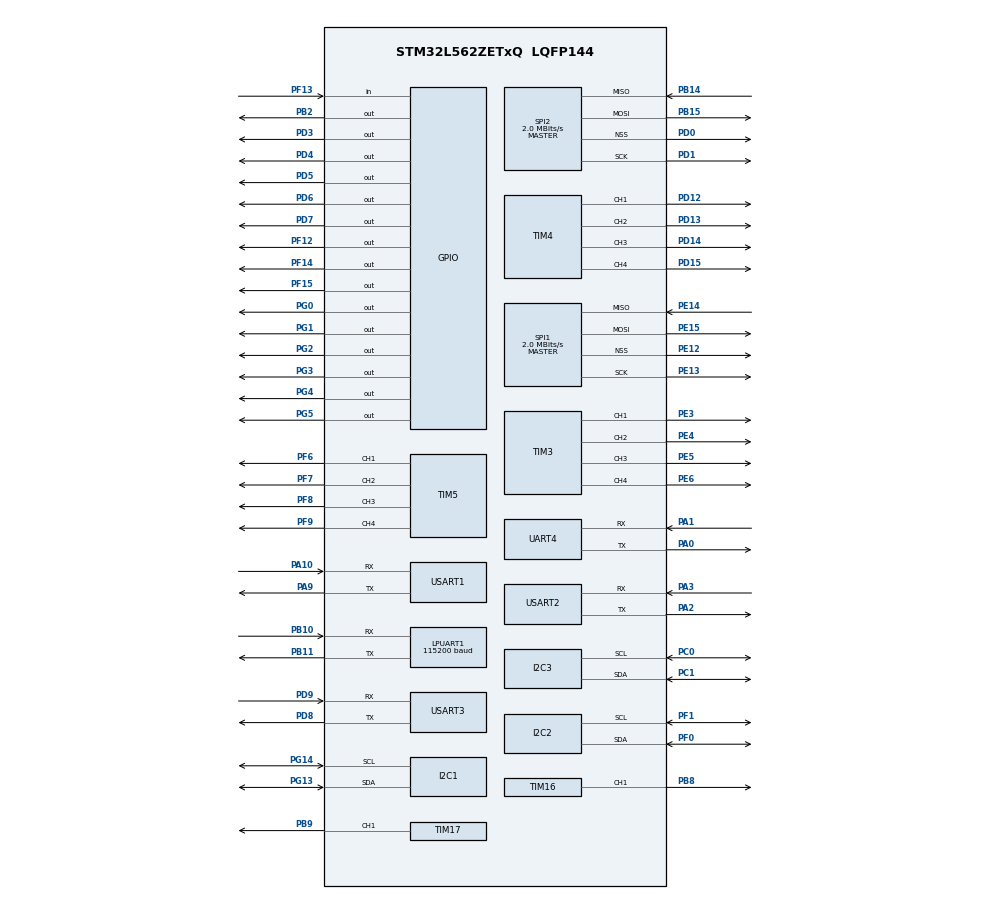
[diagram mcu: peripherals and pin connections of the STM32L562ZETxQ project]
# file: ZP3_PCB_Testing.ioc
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LPUART1.BaudRate=115200
Mcu.Family=STM32L5
Mcu.Name=STM32L562ZETxQ
Mcu.Package=LQFP144
NVIC.PriorityGroup=NVIC_PRIORITYGROUP_3
PA0.Mode=Asynchronous
PA0.Signal=UART4_TX
PA1.Mode=Asynchronous
PA1.Signal=UART4_RX
PA10.Mode=Asynchronous
PA10.Signal=USART1_RX
PA2.Mode=Asynchronous
PA2.Signal=USART2_TX
PA3.Mode=Asynchronous
PA3.Signal=USART2_RX
PA9.Mode=Asynchronous
PA9.Signal=USART1_TX
PB10.Mode=Asynchronous
PB10.Signal=LPUART1_RX
PB11.Mode=Asynchronous
PB11.Signal=LPUART1_TX
PB14.Mode=Full_Duplex_Master
PB14.Signal=SPI2_MISO
PB15.Mode=Full_Duplex_Master
PB15.Signal=SPI2_MOSI
PB2.Signal=GPIO_Output
PB8.Signal=S_TIM16_CH1
PB9.Signal=S_TIM17_CH1
PC0.Mode=I2C
PC0.Signal=I2C3_SCL
PC1.Mode=I2C
PC1.Signal=I2C3_SDA
PD0.Mode=NSS_Signal_Hard_Output
PD0.Signal=SPI2_NSS
PD1.Mode=Full_Duplex_Master
PD1.Signal=SPI2_SCK
PD12.Signal=S_TIM4_CH1
PD13.Signal=S_TIM4_CH2
PD14.Signal=S_TIM4_CH3
PD15.Signal=S_TIM4_CH4
PD3.Signal=GPIO_Output
PD4.Signal=GPIO_Output
PD5.Signal=GPIO_Output
PD6.Signal=GPIO_Output
PD7.Signal=GPIO_Output
PD8.Mode=Asynchronous
PD8.Signal=USART3_TX
PD9.Mode=Asynchronous
PD9.Signal=USART3_RX
PE12.Mode=NSS_Signal_Hard_Output
PE12.Signal=SPI1_NSS
PE13.Mode=Full_Duplex_Master
PE13.Signal=SPI1_SCK
PE14.Mode=Full_Duplex_Master
PE14.Signal=SPI1_MISO
PE15.Mode=Full_Duplex_Master
PE15.Signal=SPI1_MOSI
PE3.Signal=S_TIM3_CH1
PE4.Signal=S_TIM3_CH2
PE5.Signal=S_TIM3_CH3
PE6.Signal=S_TIM3_CH4
PF0.Mode=I2C
PF0.Signal=I2C2_SDA
PF1.Mode=I2C
PF1.Signal=I2C2_SCL
PF12.Signal=GPIO_Output
PF13.Signal=GPIO_Input
PF14.Signal=GPIO_Output
PF15.Signal=GPIO_Output
PF6.Signal=S_TIM5_CH1
PF7.Signal=S_TIM5_CH2
PF8.Signal=S_TIM5_CH3
PF9.Signal=S_TIM5_CH4
PG0.Signal=GPIO_Output
PG1.Signal=GPIO_Output
PG13.Mode=I2C
PG13.Signal=I2C1_SDA
PG14.Mode=I2C
PG14.Signal=I2C1_SCL
PG2.Signal=GPIO_Output
PG3.Signal=GPIO_Output
PG4.Signal=GPIO_Output
PG5.Signal=GPIO_Output
ProjectManager.HeapSize=0x200
ProjectManager.StackSize=0x400
ProjectManager.TargetToolchain=STM32CubeIDE
RCC.HSE_VALUE=16000000
RCC.HSI48_VALUE=48000000
RCC.HSI_VALUE=16000000
RCC.LSE_VALUE=32768
RCC.MSI_VALUE=4000000
RCC.VCOOutputFreq_Value=32000000
SH.S_TIM16_CH1.0=TIM16_CH1,PWM Generation1 CH1
SH.S_TIM17_CH1.0=TIM17_CH1,PWM Generation1 CH1
SH.S_TIM3_CH1.0=TIM3_CH1,PWM Generation1 CH1
SH.S_TIM3_CH2.0=TIM3_CH2,PWM Generation2 CH2
SH.S_TIM3_CH3.0=TIM3_CH3,PWM Generation3 CH3
SH.S_TIM3_CH4.0=TIM3_CH4,PWM Generation4 CH4
SH.S_TIM4_CH1.0=TIM4_CH1,PWM Generation1 CH1
SH.S_TIM4_CH2.0=TIM4_CH2,PWM Generation2 CH2
SH.S_TIM4_CH3.0=TIM4_CH3,PWM Generation3 CH3
SH.S_TIM4_CH4.0=TIM4_CH4,PWM Generation4 CH4
SH.S_TIM5_CH1.0=TIM5_CH1,PWM Generation1 CH1
SH.S_TIM5_CH2.0=TIM5_CH2,PWM Generation2 CH2
SH.S_TIM5_CH3.0=TIM5_CH3,PWM Generation3 CH3
SH.S_TIM5_CH4.0=TIM5_CH4,PWM Generation4 CH4
SPI1.CalculateBaudRate=2.0 MBits/s
SPI1.Direction=SPI_DIRECTION_2LINES
SPI1.Mode=SPI_MODE_MASTER
SPI1.VirtualNSS=VM_NSSHARD
SPI1.VirtualType=VM_MASTER
SPI2.CalculateBaudRate=2.0 MBits/s
SPI2.DataSize=SPI_DATASIZE_8BIT
SPI2.Direction=SPI_DIRECTION_2LINES
SPI2.Mode=SPI_MODE_MASTER
SPI2.VirtualNSS=VM_NSSHARD
SPI2.VirtualType=VM_MASTER
TIM16.Channel=TIM_CHANNEL_1
TIM17.Channel=TIM_CHANNEL_1
TIM3.Channel-PWM\ Generation1\ CH1=TIM_CHANNEL_1
TIM3.Channel-PWM\ Generation2\ CH2=TIM_CHANNEL_2
TIM3.Channel-PWM\ Generation3\ CH3=TIM_CHANNEL_3
TIM3.Channel-PWM\ Generation4\ CH4=TIM_CHANNEL_4
TIM4.Channel-PWM\ Generation1\ CH1=TIM_CHANNEL_1
TIM4.Channel-PWM\ Generation2\ CH2=TIM_CHANNEL_2
TIM4.Channel-PWM\ Generation3\ CH3=TIM_CHANNEL_3
TIM4.Channel-PWM\ Generation4\ CH4=TIM_CHANNEL_4
TIM5.Channel-PWM\ Generation1\ CH1=TIM_CHANNEL_1
TIM5.Channel-PWM\ Generation2\ CH2=TIM_CHANNEL_2
TIM5.Channel-PWM\ Generation3\ CH3=TIM_CHANNEL_3
TIM5.Channel-PWM\ Generation4\ CH4=TIM_CHANNEL_4
USART1.VirtualMode-Asynchronous=VM_ASYNC
USART2.VirtualMode-Asynchronous=VM_ASYNC
USART3.VirtualMode-Asynchronous=VM_ASYNC
VP_TIM16_VS_ClockSourceINT.Mode=Enable_Timer
VP_TIM17_VS_ClockSourceINT.Mode=Enable_Timer
board=custom

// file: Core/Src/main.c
/* USER CODE BEGIN Header */
/**
  ******************************************************************************
  * @file           : main.c
  * @brief          : Main program body
  ******************************************************************************
  * @attention
  *
  * Copyright (c) 2023 STMicroelectronics.
  * All rights reserved.
  *
  * This software is licensed under terms that can be found in the LICENSE file
  * in the root directory of this software component.
  * If no LICENSE file comes with this software, it is provided AS-IS.
  *
  ******************************************************************************
  */
/* USER CODE END Header */
#include "main.h"

I2C_HandleTypeDef hi2c1;
I2C_HandleTypeDef hi2c2;
I2C_HandleTypeDef hi2c3;

UART_HandleTypeDef hlpuart1;
UART_HandleTypeDef huart4;
UART_HandleTypeDef huart1;
UART_HandleTypeDef huart2;
UART_HandleTypeDef huart3;

SPI_HandleTypeDef hspi1;
SPI_HandleTypeDef hspi2;

TIM_HandleTypeDef htim3;
TIM_HandleTypeDef htim4;
TIM_HandleTypeDef htim5;
TIM_HandleTypeDef htim16;
TIM_HandleTypeDef htim17;

void SystemClock_Config(void);
static void MX_GPIO_Init(void);
static void MX_I2C1_Init(void);
static void MX_I2C2_Init(void);
static void MX_I2C3_Init(void);
static void MX_LPUART1_UART_Init(void);
static void MX_UART4_Init(void);
static void MX_USART1_UART_Init(void);
static void MX_USART2_UART_Init(void);
static void MX_USART3_UART_Init(void);
static void MX_SPI1_Init(void);
static void MX_SPI2_Init(void);
static void MX_TIM3_Init(void);
static void MX_TIM4_Init(void);
static void MX_TIM5_Init(void);
static void MX_TIM16_Init(void);
static void MX_TIM17_Init(void);

/* USER CODE BEGIN 0 */
void toggle_all_GPIO(void)
{

	HAL_GPIO_TogglePin(GPIOB, GPIO_PIN_2);

	  /*Configure GPIO pin Output Level */
	HAL_GPIO_TogglePin(GPIOF, GPIO_PIN_12|GPIO_PIN_14|GPIO_PIN_15);

	  /*Configure GPIO pin Output Level */
	HAL_GPIO_TogglePin(GPIOG, GPIO_PIN_0|GPIO_PIN_1|GPIO_PIN_2|GPIO_PIN_3
	                          |GPIO_PIN_4|GPIO_PIN_5);

	  /*Configure GPIO pin Output Level */
	HAL_GPIO_TogglePin(GPIOD, GPIO_PIN_3|GPIO_PIN_4|GPIO_PIN_5|GPIO_PIN_6
	                          |GPIO_PIN_7);
}

/* USER CODE END 0 */

int main(void)
{

  /* MCU Configuration--------------------------------------------------------*/

  /* Reset of all peripherals, Initializes the Flash interface and the Systick. */
  HAL_Init();

  /* Configure the system clock */
  SystemClock_Config();

  /* Initialize all configured peripherals */
  MX_GPIO_Init();
  MX_I2C1_Init();
  MX_I2C2_Init();
  MX_I2C3_Init();
  MX_LPUART1_UART_Init();
  MX_UART4_Init();
  MX_USART1_UART_Init();
  MX_USART2_UART_Init();
  MX_USART3_UART_Init();
  MX_SPI1_Init();
  MX_SPI2_Init();
  MX_TIM3_Init();
  MX_TIM4_Init();
  MX_TIM5_Init();
  MX_TIM16_Init();
  MX_TIM17_Init();

  /* Infinite loop */
  while (1)
  {
	  toggle_all_GPIO();
	  HAL_Delay(500);
  }
}

void SystemClock_Config(void)
{
  RCC_OscInitTypeDef RCC_OscInitStruct = {0};
  RCC_ClkInitTypeDef RCC_ClkInitStruct = {0};

  /** Configure the main internal regulator output voltage
  */
  if (HAL_PWREx_ControlVoltageScaling(PWR_REGULATOR_VOLTAGE_SCALE2) != HAL_OK)
  {
    Error_Handler();
  }

  /** Initializes the RCC Oscillators according to the specified parameters
  * in the RCC_OscInitTypeDef structure.
  */
  RCC_OscInitStruct.OscillatorType = RCC_OSCILLATORTYPE_MSI;
  RCC_OscInitStruct.MSIState = RCC_MSI_ON;
  RCC_OscInitStruct.MSICalibrationValue = RCC_MSICALIBRATION_DEFAULT;
  RCC_OscInitStruct.MSIClockRange = RCC_MSIRANGE_6;
  RCC_OscInitStruct.PLL.PLLState = RCC_PLL_NONE;
  if (HAL_RCC_OscConfig(&RCC_OscInitStruct) != HAL_OK)
  {
    Error_Handler();
  }

  /** Initializes the CPU, AHB and APB buses clocks
  */
  RCC_ClkInitStruct.ClockType = RCC_CLOCKTYPE_HCLK|RCC_CLOCKTYPE_SYSCLK
                              |RCC_CLOCKTYPE_PCLK1|RCC_CLOCKTYPE_PCLK2;
  RCC_ClkInitStruct.SYSCLKSource = RCC_SYSCLKSOURCE_MSI;
  RCC_ClkInitStruct.AHBCLKDivider = RCC_SYSCLK_DIV1;
  RCC_ClkInitStruct.APB1CLKDivider = RCC_HCLK_DIV1;
  RCC_ClkInitStruct.APB2CLKDivider = RCC_HCLK_DIV1;

  if (HAL_RCC_ClockConfig(&RCC_ClkInitStruct, FLASH_LATENCY_0) != HAL_OK)
  {
    Error_Handler();
  }
}

static void MX_I2C1_Init(void)
{

  hi2c1.Instance = I2C1;
  hi2c1.Init.Timing = 0x00000E14;
  hi2c1.Init.OwnAddress1 = 0;
  hi2c1.Init.AddressingMode = I2C_ADDRESSINGMODE_7BIT;
  hi2c1.Init.DualAddressMode = I2C_DUALADDRESS_DISABLE;
  hi2c1.Init.OwnAddress2 = 0;
  hi2c1.Init.OwnAddress2Masks = I2C_OA2_NOMASK;
  hi2c1.Init.GeneralCallMode = I2C_GENERALCALL_DISABLE;
  hi2c1.Init.NoStretchMode = I2C_NOSTRETCH_DISABLE;
  if (HAL_I2C_Init(&hi2c1) != HAL_OK)
  {
    Error_Handler();
  }

  /** Configure Analogue filter
  */
  if (HAL_I2CEx_ConfigAnalogFilter(&hi2c1, I2C_ANALOGFILTER_ENABLE) != HAL_OK)
  {
    Error_Handler();
  }

  /** Configure Digital filter
  */
  if (HAL_I2CEx_ConfigDigitalFilter(&hi2c1, 0) != HAL_OK)
  {
    Error_Handler();
  }

}

static void MX_I2C2_Init(void)
{

  hi2c2.Instance = I2C2;
  hi2c2.Init.Timing = 0x00000E14;
  hi2c2.Init.OwnAddress1 = 0;
  hi2c2.Init.AddressingMode = I2C_ADDRESSINGMODE_7BIT;
  hi2c2.Init.DualAddressMode = I2C_DUALADDRESS_DISABLE;
  hi2c2.Init.OwnAddress2 = 0;
  hi2c2.Init.OwnAddress2Masks = I2C_OA2_NOMASK;
  hi2c2.Init.GeneralCallMode = I2C_GENERALCALL_DISABLE;
  hi2c2.Init.NoStretchMode = I2C_NOSTRETCH_DISABLE;
  if (HAL_I2C_Init(&hi2c2) != HAL_OK)
  {
    Error_Handler();
  }

  /** Configure Analogue filter
  */
  if (HAL_I2CEx_ConfigAnalogFilter(&hi2c2, I2C_ANALOGFILTER_ENABLE) != HAL_OK)
  {
    Error_Handler();
  }

  /** Configure Digital filter
  */
  if (HAL_I2CEx_ConfigDigitalFilter(&hi2c2, 0) != HAL_OK)
  {
    Error_Handler();
  }

}

static void MX_I2C3_Init(void)
{

  hi2c3.Instance = I2C3;
  hi2c3.Init.Timing = 0x00000E14;
  hi2c3.Init.OwnAddress1 = 0;
  hi2c3.Init.AddressingMode = I2C_ADDRESSINGMODE_7BIT;
  hi2c3.Init.DualAddressMode = I2C_DUALADDRESS_DISABLE;
  hi2c3.Init.OwnAddress2 = 0;
  hi2c3.Init.OwnAddress2Masks = I2C_OA2_NOMASK;
  hi2c3.Init.GeneralCallMode = I2C_GENERALCALL_DISABLE;
  hi2c3.Init.NoStretchMode = I2C_NOSTRETCH_DISABLE;
  if (HAL_I2C_Init(&hi2c3) != HAL_OK)
  {
    Error_Handler();
  }

  /** Configure Analogue filter
  */
  if (HAL_I2CEx_ConfigAnalogFilter(&hi2c3, I2C_ANALOGFILTER_ENABLE) != HAL_OK)
  {
    Error_Handler();
  }

  /** Configure Digital filter
  */
  if (HAL_I2CEx_ConfigDigitalFilter(&hi2c3, 0) != HAL_OK)
  {
    Error_Handler();
  }

}

static void MX_LPUART1_UART_Init(void)
{

  hlpuart1.Instance = LPUART1;
  hlpuart1.Init.BaudRate = 115200;
  hlpuart1.Init.WordLength = UART_WORDLENGTH_8B;
  hlpuart1.Init.StopBits = UART_STOPBITS_1;
  hlpuart1.Init.Parity = UART_PARITY_NONE;
  hlpuart1.Init.Mode = UART_MODE_TX_RX;
  hlpuart1.Init.HwFlowCtl = UART_HWCONTROL_NONE;
  hlpuart1.Init.OneBitSampling = UART_ONE_BIT_SAMPLE_DISABLE;
  hlpuart1.Init.ClockPrescaler = UART_PRESCALER_DIV1;
  hlpuart1.AdvancedInit.AdvFeatureInit = UART_ADVFEATURE_NO_INIT;
  hlpuart1.FifoMode = UART_FIFOMODE_DISABLE;
  if (HAL_UART_Init(&hlpuart1) != HAL_OK)
  {
    Error_Handler();
  }
  if (HAL_UARTEx_SetTxFifoThreshold(&hlpuart1, UART_TXFIFO_THRESHOLD_1_8) != HAL_OK)
  {
    Error_Handler();
  }
  if (HAL_UARTEx_SetRxFifoThreshold(&hlpuart1, UART_RXFIFO_THRESHOLD_1_8) != HAL_OK)
  {
    Error_Handler();
  }
  if (HAL_UARTEx_DisableFifoMode(&hlpuart1) != HAL_OK)
  {
    Error_Handler();
  }

}

static void MX_UART4_Init(void)
{

  huart4.Instance = UART4;
  huart4.Init.BaudRate = 115200;
  huart4.Init.WordLength = UART_WORDLENGTH_8B;
  huart4.Init.StopBits = UART_STOPBITS_1;
  huart4.Init.Parity = UART_PARITY_NONE;
  huart4.Init.Mode = UART_MODE_TX_RX;
  huart4.Init.HwFlowCtl = UART_HWCONTROL_NONE;
  huart4.Init.OverSampling = UART_OVERSAMPLING_16;
  huart4.Init.OneBitSampling = UART_ONE_BIT_SAMPLE_DISABLE;
  huart4.Init.ClockPrescaler = UART_PRESCALER_DIV1;
  huart4.AdvancedInit.AdvFeatureInit = UART_ADVFEATURE_NO_INIT;
  if (HAL_UART_Init(&huart4) != HAL_OK)
  {
    Error_Handler();
  }
  if (HAL_UARTEx_SetTxFifoThreshold(&huart4, UART_TXFIFO_THRESHOLD_1_8) != HAL_OK)
  {
    Error_Handler();
  }
  if (HAL_UARTEx_SetRxFifoThreshold(&huart4, UART_RXFIFO_THRESHOLD_1_8) != HAL_OK)
  {
    Error_Handler();
  }
  if (HAL_UARTEx_DisableFifoMode(&huart4) != HAL_OK)
  {
    Error_Handler();
  }

}

static void MX_USART1_UART_Init(void)
{

  huart1.Instance = USART1;
  huart1.Init.BaudRate = 115200;
  huart1.Init.WordLength = UART_WORDLENGTH_8B;
  huart1.Init.StopBits = UART_STOPBITS_1;
  huart1.Init.Parity = UART_PARITY_NONE;
  huart1.Init.Mode = UART_MODE_TX_RX;
  huart1.Init.HwFlowCtl = UART_HWCONTROL_NONE;
  huart1.Init.OverSampling = UART_OVERSAMPLING_16;
  huart1.Init.OneBitSampling = UART_ONE_BIT_SAMPLE_DISABLE;
  huart1.Init.ClockPrescaler = UART_PRESCALER_DIV1;
  huart1.AdvancedInit.AdvFeatureInit = UART_ADVFEATURE_NO_INIT;
  if (HAL_UART_Init(&huart1) != HAL_OK)
  {
    Error_Handler();
  }
  if (HAL_UARTEx_SetTxFifoThreshold(&huart1, UART_TXFIFO_THRESHOLD_1_8) != HAL_OK)
  {
    Error_Handler();
  }
  if (HAL_UARTEx_SetRxFifoThreshold(&huart1, UART_RXFIFO_THRESHOLD_1_8) != HAL_OK)
  {
    Error_Handler();
  }
  if (HAL_UARTEx_DisableFifoMode(&huart1) != HAL_OK)
  {
    Error_Handler();
  }

}

static void MX_USART2_UART_Init(void)
{

  huart2.Instance = USART2;
  huart2.Init.BaudRate = 115200;
  huart2.Init.WordLength = UART_WORDLENGTH_8B;
  huart2.Init.StopBits = UART_STOPBITS_1;
  huart2.Init.Parity = UART_PARITY_NONE;
  huart2.Init.Mode = UART_MODE_TX_RX;
  huart2.Init.HwFlowCtl = UART_HWCONTROL_NONE;
  huart2.Init.OverSampling = UART_OVERSAMPLING_16;
  huart2.Init.OneBitSampling = UART_ONE_BIT_SAMPLE_DISABLE;
  huart2.Init.ClockPrescaler = UART_PRESCALER_DIV1;
  huart2.AdvancedInit.AdvFeatureInit = UART_ADVFEATURE_NO_INIT;
  if (HAL_UART_Init(&huart2) != HAL_OK)
  {
    Error_Handler();
  }
  if (HAL_UARTEx_SetTxFifoThreshold(&huart2, UART_TXFIFO_THRESHOLD_1_8) != HAL_OK)
  {
    Error_Handler();
  }
  if (HAL_UARTEx_SetRxFifoThreshold(&huart2, UART_RXFIFO_THRESHOLD_1_8) != HAL_OK)
  {
    Error_Handler();
  }
  if (HAL_UARTEx_DisableFifoMode(&huart2) != HAL_OK)
  {
    Error_Handler();
  }

}

static void MX_USART3_UART_Init(void)
{

  huart3.Instance = USART3;
  huart3.Init.BaudRate = 115200;
  huart3.Init.WordLength = UART_WORDLENGTH_8B;
  huart3.Init.StopBits = UART_STOPBITS_1;
  huart3.Init.Parity = UART_PARITY_NONE;
  huart3.Init.Mode = UART_MODE_TX_RX;
  huart3.Init.HwFlowCtl = UART_HWCONTROL_NONE;
  huart3.Init.OverSampling = UART_OVERSAMPLING_16;
  huart3.Init.OneBitSampling = UART_ONE_BIT_SAMPLE_DISABLE;
  huart3.Init.ClockPrescaler = UART_PRESCALER_DIV1;
  huart3.AdvancedInit.AdvFeatureInit = UART_ADVFEATURE_NO_INIT;
  if (HAL_UART_Init(&huart3) != HAL_OK)
  {
    Error_Handler();
  }
  if (HAL_UARTEx_SetTxFifoThreshold(&huart3, UART_TXFIFO_THRESHOLD_1_8) != HAL_OK)
  {
    Error_Handler();
  }
  if (HAL_UARTEx_SetRxFifoThreshold(&huart3, UART_RXFIFO_THRESHOLD_1_8) != HAL_OK)
  {
    Error_Handler();
  }
  if (HAL_UARTEx_DisableFifoMode(&huart3) != HAL_OK)
  {
    Error_Handler();
  }

}

static void MX_SPI1_Init(void)
{

  /* SPI1 parameter configuration*/
  hspi1.Instance = SPI1;
  hspi1.Init.Mode = SPI_MODE_MASTER;
  hspi1.Init.Direction = SPI_DIRECTION_2LINES;
  hspi1.Init.DataSize = SPI_DATASIZE_4BIT;
  hspi1.Init.CLKPolarity = SPI_POLARITY_LOW;
  hspi1.Init.CLKPhase = SPI_PHASE_1EDGE;
  hspi1.Init.NSS = SPI_NSS_HARD_OUTPUT;
  hspi1.Init.BaudRatePrescaler = SPI_BAUDRATEPRESCALER_2;
  hspi1.Init.FirstBit = SPI_FIRSTBIT_MSB;
  hspi1.Init.TIMode = SPI_TIMODE_DISABLE;
  hspi1.Init.CRCCalculation = SPI_CRCCALCULATION_DISABLE;
  hspi1.Init.CRCPolynomial = 7;
  hspi1.Init.CRCLength = SPI_CRC_LENGTH_DATASIZE;
  hspi1.Init.NSSPMode = SPI_NSS_PULSE_ENABLE;
  if (HAL_SPI_Init(&hspi1) != HAL_OK)
  {
    Error_Handler();
  }

}

static void MX_SPI2_Init(void)
{

  /* SPI2 parameter configuration*/
  hspi2.Instance = SPI2;
  hspi2.Init.Mode = SPI_MODE_MASTER;
  hspi2.Init.Direction = SPI_DIRECTION_2LINES;
  hspi2.Init.DataSize = SPI_DATASIZE_8BIT;
  hspi2.Init.CLKPolarity = SPI_POLARITY_LOW;
  hspi2.Init.CLKPhase = SPI_PHASE_1EDGE;
  hspi2.Init.NSS = SPI_NSS_HARD_OUTPUT;
  hspi2.Init.BaudRatePrescaler = SPI_BAUDRATEPRESCALER_2;
  hspi2.Init.FirstBit = SPI_FIRSTBIT_MSB;
  hspi2.Init.TIMode = SPI_TIMODE_DISABLE;
  hspi2.Init.CRCCalculation = SPI_CRCCALCULATION_DISABLE;
  hspi2.Init.CRCPolynomial = 7;
  hspi2.Init.CRCLength = SPI_CRC_LENGTH_DATASIZE;
  hspi2.Init.NSSPMode = SPI_NSS_PULSE_ENABLE;
  if (HAL_SPI_Init(&hspi2) != HAL_OK)
  {
    Error_Handler();
  }

}

static void MX_TIM3_Init(void)
{

  TIM_MasterConfigTypeDef sMasterConfig = {0};
  TIM_OC_InitTypeDef sConfigOC = {0};

  htim3.Instance = TIM3;
  htim3.Init.Prescaler = 0;
  htim3.Init.CounterMode = TIM_COUNTERMODE_UP;
  htim3.Init.Period = 65535;
  htim3.Init.ClockDivision = TIM_CLOCKDIVISION_DIV1;
  htim3.Init.AutoReloadPreload = TIM_AUTORELOAD_PRELOAD_DISABLE;
  if (HAL_TIM_PWM_Init(&htim3) != HAL_OK)
  {
    Error_Handler();
  }
  sMasterConfig.MasterOutputTrigger = TIM_TRGO_RESET;
  sMasterConfig.MasterSlaveMode = TIM_MASTERSLAVEMODE_DISABLE;
  if (HAL_TIMEx_MasterConfigSynchronization(&htim3, &sMasterConfig) != HAL_OK)
  {
    Error_Handler();
  }
  sConfigOC.OCMode = TIM_OCMODE_PWM1;
  sConfigOC.Pulse = 0;
  sConfigOC.OCPolarity = TIM_OCPOLARITY_HIGH;
  sConfigOC.OCFastMode = TIM_OCFAST_DISABLE;
  if (HAL_TIM_PWM_ConfigChannel(&htim3, &sConfigOC, TIM_CHANNEL_1) != HAL_OK)
  {
    Error_Handler();
  }
  if (HAL_TIM_PWM_ConfigChannel(&htim3, &sConfigOC, TIM_CHANNEL_2) != HAL_OK)
  {
    Error_Handler();
  }
  if (HAL_TIM_PWM_ConfigChannel(&htim3, &sConfigOC, TIM_CHANNEL_3) != HAL_OK)
  {
    Error_Handler();
  }
  if (HAL_TIM_PWM_ConfigChannel(&htim3, &sConfigOC, TIM_CHANNEL_4) != HAL_OK)
  {
    Error_Handler();
  }
  HAL_TIM_MspPostInit(&htim3);

}

static void MX_TIM4_Init(void)
{

  TIM_MasterConfigTypeDef sMasterConfig = {0};
  TIM_OC_InitTypeDef sConfigOC = {0};

  htim4.Instance = TIM4;
  htim4.Init.Prescaler = 0;
  htim4.Init.CounterMode = TIM_COUNTERMODE_UP;
  htim4.Init.Period = 65535;
  htim4.Init.ClockDivision = TIM_CLOCKDIVISION_DIV1;
  htim4.Init.AutoReloadPreload = TIM_AUTORELOAD_PRELOAD_DISABLE;
  if (HAL_TIM_PWM_Init(&htim4) != HAL_OK)
  {
    Error_Handler();
  }
  sMasterConfig.MasterOutputTrigger = TIM_TRGO_RESET;
  sMasterConfig.MasterSlaveMode = TIM_MASTERSLAVEMODE_DISABLE;
  if (HAL_TIMEx_MasterConfigSynchronization(&htim4, &sMasterConfig) != HAL_OK)
  {
    Error_Handler();
  }
  sConfigOC.OCMode = TIM_OCMODE_PWM1;
  sConfigOC.Pulse = 0;
  sConfigOC.OCPolarity = TIM_OCPOLARITY_HIGH;
  sConfigOC.OCFastMode = TIM_OCFAST_DISABLE;
  if (HAL_TIM_PWM_ConfigChannel(&htim4, &sConfigOC, TIM_CHANNEL_1) != HAL_OK)
  {
    Error_Handler();
  }
  if (HAL_TIM_PWM_ConfigChannel(&htim4, &sConfigOC, TIM_CHANNEL_2) != HAL_OK)
  {
    Error_Handler();
  }
  if (HAL_TIM_PWM_ConfigChannel(&htim4, &sConfigOC, TIM_CHANNEL_3) != HAL_OK)
  {
    Error_Handler();
  }
  if (HAL_TIM_PWM_ConfigChannel(&htim4, &sConfigOC, TIM_CHANNEL_4) != HAL_OK)
  {
    Error_Handler();
  }
  HAL_TIM_MspPostInit(&htim4);

}

static void MX_TIM5_Init(void)
{

  TIM_MasterConfigTypeDef sMasterConfig = {0};
  TIM_OC_InitTypeDef sConfigOC = {0};

  htim5.Instance = TIM5;
  htim5.Init.Prescaler = 0;
  htim5.Init.CounterMode = TIM_COUNTERMODE_UP;
  htim5.Init.Period = 4294967295;
  htim5.Init.ClockDivision = TIM_CLOCKDIVISION_DIV1;
  htim5.Init.AutoReloadPreload = TIM_AUTORELOAD_PRELOAD_DISABLE;
  if (HAL_TIM_PWM_Init(&htim5) != HAL_OK)
  {
    Error_Handler();
  }
  sMasterConfig.MasterOutputTrigger = TIM_TRGO_RESET;
  sMasterConfig.MasterSlaveMode = TIM_MASTERSLAVEMODE_DISABLE;
  if (HAL_TIMEx_MasterConfigSynchronization(&htim5, &sMasterConfig) != HAL_OK)
  {
    Error_Handler();
  }
  sConfigOC.OCMode = TIM_OCMODE_PWM1;
  sConfigOC.Pulse = 0;
  sConfigOC.OCPolarity = TIM_OCPOLARITY_HIGH;
  sConfigOC.OCFastMode = TIM_OCFAST_DISABLE;
  if (HAL_TIM_PWM_ConfigChannel(&htim5, &sConfigOC, TIM_CHANNEL_1) != HAL_OK)
  {
    Error_Handler();
  }
  if (HAL_TIM_PWM_ConfigChannel(&htim5, &sConfigOC, TIM_CHANNEL_2) != HAL_OK)
  {
    Error_Handler();
  }
  if (HAL_TIM_PWM_ConfigChannel(&htim5, &sConfigOC, TIM_CHANNEL_3) != HAL_OK)
  {
    Error_Handler();
  }
  if (HAL_TIM_PWM_ConfigChannel(&htim5, &sConfigOC, TIM_CHANNEL_4) != HAL_OK)
  {
    Error_Handler();
  }
  HAL_TIM_MspPostInit(&htim5);

}

static void MX_TIM16_Init(void)
{

  TIM_OC_InitTypeDef sConfigOC = {0};
  TIM_BreakDeadTimeConfigTypeDef sBreakDeadTimeConfig = {0};

  htim16.Instance = TIM16;
  htim16.Init.Prescaler = 0;
  htim16.Init.CounterMode = TIM_COUNTERMODE_UP;
  htim16.Init.Period = 65535;
  htim16.Init.ClockDivision = TIM_CLOCKDIVISION_DIV1;
  htim16.Init.RepetitionCounter = 0;
  htim16.Init.AutoReloadPreload = TIM_AUTORELOAD_PRELOAD_DISABLE;
  if (HAL_TIM_Base_Init(&htim16) != HAL_OK)
  {
    Error_Handler();
  }
  if (HAL_TIM_PWM_Init(&htim16) != HAL_OK)
  {
    Error_Handler();
  }
  sConfigOC.OCMode = TIM_OCMODE_PWM1;
  sConfigOC.Pulse = 0;
  sConfigOC.OCPolarity = TIM_OCPOLARITY_HIGH;
  sConfigOC.OCNPolarity = TIM_OCNPOLARITY_HIGH;
  sConfigOC.OCFastMode = TIM_OCFAST_DISABLE;
  sConfigOC.OCIdleState = TIM_OCIDLESTATE_RESET;
  sConfigOC.OCNIdleState = TIM_OCNIDLESTATE_RESET;
  if (HAL_TIM_PWM_ConfigChannel(&htim16, &sConfigOC, TIM_CHANNEL_1) != HAL_OK)
  {
    Error_Handler();
  }
  sBreakDeadTimeConfig.OffStateRunMode = TIM_OSSR_DISABLE;
  sBreakDeadTimeConfig.OffStateIDLEMode = TIM_OSSI_DISABLE;
  sBreakDeadTimeConfig.LockLevel = TIM_LOCKLEVEL_OFF;
  sBreakDeadTimeConfig.DeadTime = 0;
  sBreakDeadTimeConfig.BreakState = TIM_BREAK_DISABLE;
  sBreakDeadTimeConfig.BreakPolarity = TIM_BREAKPOLARITY_HIGH;
  sBreakDeadTimeConfig.BreakFilter = 0;
  sBreakDeadTimeConfig.AutomaticOutput = TIM_AUTOMATICOUTPUT_DISABLE;
  if (HAL_TIMEx_ConfigBreakDeadTime(&htim16, &sBreakDeadTimeConfig) != HAL_OK)
  {
    Error_Handler();
  }
  HAL_TIM_MspPostInit(&htim16);

}

static void MX_TIM17_Init(void)
{

  TIM_OC_InitTypeDef sConfigOC = {0};
  TIM_BreakDeadTimeConfigTypeDef sBreakDeadTimeConfig = {0};

  htim17.Instance = TIM17;
  htim17.Init.Prescaler = 0;
  htim17.Init.CounterMode = TIM_COUNTERMODE_UP;
  htim17.Init.Period = 65535;
  htim17.Init.ClockDivision = TIM_CLOCKDIVISION_DIV1;
  htim17.Init.RepetitionCounter = 0;
  htim17.Init.AutoReloadPreload = TIM_AUTORELOAD_PRELOAD_DISABLE;
  if (HAL_TIM_Base_Init(&htim17) != HAL_OK)
  {
    Error_Handler();
  }
  if (HAL_TIM_PWM_Init(&htim17) != HAL_OK)
  {
    Error_Handler();
  }
  sConfigOC.OCMode = TIM_OCMODE_PWM1;
  sConfigOC.Pulse = 0;
  sConfigOC.OCPolarity = TIM_OCPOLARITY_HIGH;
  sConfigOC.OCNPolarity = TIM_OCNPOLARITY_HIGH;
  sConfigOC.OCFastMode = TIM_OCFAST_DISABLE;
  sConfigOC.OCIdleState = TIM_OCIDLESTATE_RESET;
  sConfigOC.OCNIdleState = TIM_OCNIDLESTATE_RESET;
  if (HAL_TIM_PWM_ConfigChannel(&htim17, &sConfigOC, TIM_CHANNEL_1) != HAL_OK)
  {
    Error_Handler();
  }
  sBreakDeadTimeConfig.OffStateRunMode = TIM_OSSR_DISABLE;
  sBreakDeadTimeConfig.OffStateIDLEMode = TIM_OSSI_DISABLE;
  sBreakDeadTimeConfig.LockLevel = TIM_LOCKLEVEL_OFF;
  sBreakDeadTimeConfig.DeadTime = 0;
  sBreakDeadTimeConfig.BreakState = TIM_BREAK_DISABLE;
  sBreakDeadTimeConfig.BreakPolarity = TIM_BREAKPOLARITY_HIGH;
  sBreakDeadTimeConfig.BreakFilter = 0;
  sBreakDeadTimeConfig.AutomaticOutput = TIM_AUTOMATICOUTPUT_DISABLE;
  if (HAL_TIMEx_ConfigBreakDeadTime(&htim17, &sBreakDeadTimeConfig) != HAL_OK)
  {
    Error_Handler();
  }
  HAL_TIM_MspPostInit(&htim17);

}

static void MX_GPIO_Init(void)
{
  GPIO_InitTypeDef GPIO_InitStruct = {0};

  /* GPIO Ports Clock Enable */
  __HAL_RCC_GPIOE_CLK_ENABLE();
  __HAL_RCC_GPIOF_CLK_ENABLE();
  __HAL_RCC_GPIOC_CLK_ENABLE();
  __HAL_RCC_GPIOA_CLK_ENABLE();
  __HAL_RCC_GPIOB_CLK_ENABLE();
  __HAL_RCC_GPIOG_CLK_ENABLE();
  __HAL_RCC_GPIOD_CLK_ENABLE();
  HAL_PWREx_EnableVddIO2();

  /*Configure GPIO pin Output Level */
  HAL_GPIO_WritePin(GPIOB, GPIO_PIN_2, GPIO_PIN_RESET);

  /*Configure GPIO pin Output Level */
  HAL_GPIO_WritePin(GPIOF, GPIO_PIN_12|GPIO_PIN_14|GPIO_PIN_15, GPIO_PIN_RESET);

  /*Configure GPIO pin Output Level */
  HAL_GPIO_WritePin(GPIOG, GPIO_PIN_0|GPIO_PIN_1|GPIO_PIN_2|GPIO_PIN_3
                          |GPIO_PIN_4|GPIO_PIN_5, GPIO_PIN_RESET);

  /*Configure GPIO pin Output Level */
  HAL_GPIO_WritePin(GPIOD, GPIO_PIN_3|GPIO_PIN_4|GPIO_PIN_5|GPIO_PIN_6
                          |GPIO_PIN_7, GPIO_PIN_RESET);

  /*Configure GPIO pin : PB2 */
  GPIO_InitStruct.Pin = GPIO_PIN_2;
  GPIO_InitStruct.Mode = GPIO_MODE_OUTPUT_PP;
  GPIO_InitStruct.Pull = GPIO_NOPULL;
  GPIO_InitStruct.Speed = GPIO_SPEED_FREQ_LOW;
  HAL_GPIO_Init(GPIOB, &GPIO_InitStruct);

  /*Configure GPIO pins : PF12 PF14 PF15 */
  GPIO_InitStruct.Pin = GPIO_PIN_12|GPIO_PIN_14|GPIO_PIN_15;
  GPIO_InitStruct.Mode = GPIO_MODE_OUTPUT_PP;
  GPIO_InitStruct.Pull = GPIO_NOPULL;
  GPIO_InitStruct.Speed = GPIO_SPEED_FREQ_LOW;
  HAL_GPIO_Init(GPIOF, &GPIO_InitStruct);

  /*Configure GPIO pin : PF13 */
  GPIO_InitStruct.Pin = GPIO_PIN_13;
  GPIO_InitStruct.Mode = GPIO_MODE_INPUT;
  GPIO_InitStruct.Pull = GPIO_NOPULL;
  HAL_GPIO_Init(GPIOF, &GPIO_InitStruct);

  /*Configure GPIO pins : PG0 PG1 PG2 PG3
                           PG4 PG5 */
  GPIO_InitStruct.Pin = GPIO_PIN_0|GPIO_PIN_1|GPIO_PIN_2|GPIO_PIN_3
                          |GPIO_PIN_4|GPIO_PIN_5;
  GPIO_InitStruct.Mode = GPIO_MODE_OUTPUT_PP;
  GPIO_InitStruct.Pull = GPIO_NOPULL;
  GPIO_InitStruct.Speed = GPIO_SPEED_FREQ_LOW;
  HAL_GPIO_Init(GPIOG, &GPIO_InitStruct);

  /*Configure GPIO pins : PD3 PD4 PD5 PD6
                           PD7 */
  GPIO_InitStruct.Pin = GPIO_PIN_3|GPIO_PIN_4|GPIO_PIN_5|GPIO_PIN_6
                          |GPIO_PIN_7;
  GPIO_InitStruct.Mode = GPIO_MODE_OUTPUT_PP;
  GPIO_InitStruct.Pull = GPIO_NOPULL;
  GPIO_InitStruct.Speed = GPIO_SPEED_FREQ_LOW;
  HAL_GPIO_Init(GPIOD, &GPIO_InitStruct);

}

void Error_Handler(void)
{
  __disable_irq();
  while (1)
  {
  }
}
